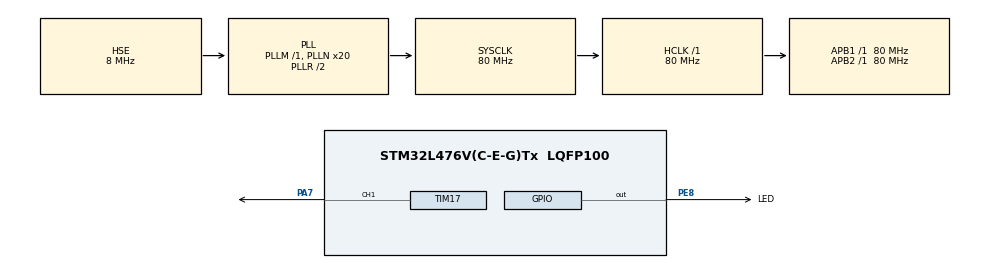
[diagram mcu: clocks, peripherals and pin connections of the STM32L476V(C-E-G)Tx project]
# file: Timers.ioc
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Mcu.Family=STM32L4
Mcu.Name=STM32L476V(C-E-G)Tx
Mcu.Package=LQFP100
NVIC.PriorityGroup=NVIC_PRIORITYGROUP_4
NVIC.TIM1_TRG_COM_TIM17_IRQn=true\:0\:0\:false\:false\:true\:true\:true\:true
PA13\ (JTMS-SWDIO).Mode=Trace_Asynchronous_SW
PA13\ (JTMS-SWDIO).Signal=SYS_JTMS-SWDIO
PA14\ (JTCK-SWCLK).Mode=Trace_Asynchronous_SW
PA14\ (JTCK-SWCLK).Signal=SYS_JTCK-SWCLK
PA7.Signal=S_TIM17_CH1
PB3\ (JTDO-TRACESWO).Mode=Trace_Asynchronous_SW
PB3\ (JTDO-TRACESWO).Signal=SYS_JTDO-SWO
PE8.GPIO_Label=LED
PE8.Signal=GPIO_Output
PH0-OSC_IN\ (PH0).Mode=HSE-External-Oscillator
PH0-OSC_IN\ (PH0).Signal=RCC_OSC_IN
PH1-OSC_OUT\ (PH1).Mode=HSE-External-Oscillator
PH1-OSC_OUT\ (PH1).Signal=RCC_OSC_OUT
ProjectManager.HeapSize=0x200
ProjectManager.StackSize=0x400
ProjectManager.TargetToolchain=STM32CubeIDE
RCC.ADCFreq_Value=32000000
RCC.AHBFreq_Value=80000000
RCC.APB1Freq_Value=80000000
RCC.APB1TimFreq_Value=80000000
RCC.APB2Freq_Value=80000000
RCC.APB2TimFreq_Value=80000000
RCC.CortexFreq_Value=80000000
RCC.HCLKFreq_Value=80000000
RCC.HSE_VALUE=8000000
RCC.HSI_VALUE=16000000
RCC.LSE_VALUE=32768
RCC.MSI_VALUE=4000000
RCC.PLLN=20
RCC.PLLSourceVirtual=RCC_PLLSOURCE_HSE
RCC.SYSCLKFreq_VALUE=80000000
RCC.SYSCLKSource=RCC_SYSCLKSOURCE_PLLCLK
RCC.USBFreq_Value=32000000
RCC.VCOOutputFreq_Value=160000000
SH.S_TIM17_CH1.0=TIM17_CH1,Output Compare1 CH1
TIM15.Period=60000-1
TIM15.Prescaler=8000-1
TIM17.Channel=TIM_CHANNEL_1
TIM17.Period=60000-1
TIM17.Prescaler=8000-1
VP_TIM15_VS_ClockSourceITR.Mode=TriggerSource_ITR3
VP_TIM15_VS_ControllerModeTrigger.Mode=Trigger Mode
VP_TIM17_VS_ClockSourceINT.Mode=Enable_Timer
board=custom

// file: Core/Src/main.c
/* USER CODE BEGIN Header */
/**
  ******************************************************************************
  * @file           : main.c
  * @brief          : Main program body
  ******************************************************************************
  * @attention
  *
  * Copyright (c) 2024 STMicroelectronics.
  * All rights reserved.
  *
  * This software is licensed under terms that can be found in the LICENSE file
  * in the root directory of this software component.
  * If no LICENSE file comes with this software, it is provided AS-IS.
  *
  ******************************************************************************
  */
/* USER CODE END Header */
#include "main.h"
#include "tim.h"
#include "gpio.h"

/* USER CODE BEGIN Includes */
#include "SWV.h"
/* USER CODE END Includes */

void SystemClock_Config(void);

int main(void)
{

  /* MCU Configuration--------------------------------------------------------*/

  /* Reset of all peripherals, Initializes the Flash interface and the Systick. */
  HAL_Init();

  /* Configure the system clock */
  SystemClock_Config();

  /* Initialize all configured peripherals */
  MX_GPIO_Init();
  MX_TIM17_Init();
  MX_TIM15_Init();
  /* USER CODE BEGIN 2 */

  HAL_TIM_Base_Start(&htim15);
  HAL_TIM_OC_Start_IT(&htim17, TIM_CHANNEL_1);
  __HAL_TIM_SET_COMPARE(&htim17, TIM_CHANNEL_1, 30000);

  /* USER CODE END 2 */

  /* Infinite loop */
  /* USER CODE BEGIN WHILE */
  int tim;
  int duty = 0;
  while (1)
  {
    /* USER CODE END WHILE */

    /* USER CODE BEGIN 3 */
	//  __HAL_TIM_SET_COUNTER(&htim17, 0);

	  tim = __HAL_TIM_GET_COUNTER(&htim17);
	  printD(tim, 0);
	  HAL_Delay(10);
	  duty += 1;
	  if(duty == 100)
	  {
		  duty = 0;
	  }
  }
  /* USER CODE END 3 */
}

void SystemClock_Config(void)
{
  RCC_OscInitTypeDef RCC_OscInitStruct = {0};
  RCC_ClkInitTypeDef RCC_ClkInitStruct = {0};

  /** Configure the main internal regulator output voltage
  */
  if (HAL_PWREx_ControlVoltageScaling(PWR_REGULATOR_VOLTAGE_SCALE1) != HAL_OK)
  {
    Error_Handler();
  }

  /** Initializes the RCC Oscillators according to the specified parameters
  * in the RCC_OscInitTypeDef structure.
  */
  RCC_OscInitStruct.OscillatorType = RCC_OSCILLATORTYPE_HSE;
  RCC_OscInitStruct.HSEState = RCC_HSE_ON;
  RCC_OscInitStruct.PLL.PLLState = RCC_PLL_ON;
  RCC_OscInitStruct.PLL.PLLSource = RCC_PLLSOURCE_HSE;
  RCC_OscInitStruct.PLL.PLLM = 1;
  RCC_OscInitStruct.PLL.PLLN = 20;
  RCC_OscInitStruct.PLL.PLLP = RCC_PLLP_DIV7;
  RCC_OscInitStruct.PLL.PLLQ = RCC_PLLQ_DIV2;
  RCC_OscInitStruct.PLL.PLLR = RCC_PLLR_DIV2;
  if (HAL_RCC_OscConfig(&RCC_OscInitStruct) != HAL_OK)
  {
    Error_Handler();
  }

  /** Initializes the CPU, AHB and APB buses clocks
  */
  RCC_ClkInitStruct.ClockType = RCC_CLOCKTYPE_HCLK|RCC_CLOCKTYPE_SYSCLK
                              |RCC_CLOCKTYPE_PCLK1|RCC_CLOCKTYPE_PCLK2;
  RCC_ClkInitStruct.SYSCLKSource = RCC_SYSCLKSOURCE_PLLCLK;
  RCC_ClkInitStruct.AHBCLKDivider = RCC_SYSCLK_DIV1;
  RCC_ClkInitStruct.APB1CLKDivider = RCC_HCLK_DIV1;
  RCC_ClkInitStruct.APB2CLKDivider = RCC_HCLK_DIV1;

  if (HAL_RCC_ClockConfig(&RCC_ClkInitStruct, FLASH_LATENCY_4) != HAL_OK)
  {
    Error_Handler();
  }
}

/* USER CODE BEGIN 4 */
void HAL_TIM_PeriodElapsedCallback(TIM_HandleTypeDef *htim)
{
	HAL_GPIO_WritePin(LED_GPIO_Port, LED_Pin, GPIO_PIN_SET);
}

void HAL_TIM_OC_DelayElapsedCallback(TIM_HandleTypeDef *htim)
{
	HAL_GPIO_WritePin(LED_GPIO_Port, LED_Pin, GPIO_PIN_RESET);
}
/* USER CODE END 4 */

void Error_Handler(void)
{
  __disable_irq();
  while (1)
  {
  }
}
